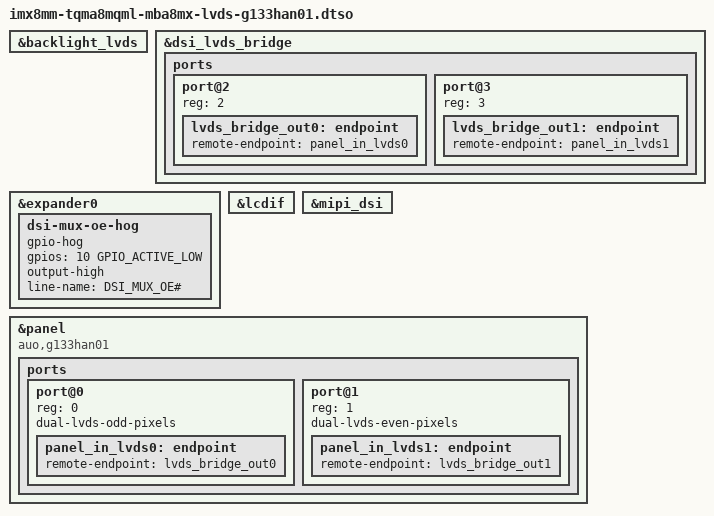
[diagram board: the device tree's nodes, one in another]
// SPDX-License-Identifier: (GPL-2.0-or-later OR MIT)
/*
 * Copyright (c) 2019-2026 TQ-Systems GmbH <linux@ew.tq-group.com>,
 * D-82229 Seefeld, Germany.
 * Author: Alexander Stein
 */

/dts-v1/;
/plugin/;

#include <dt-bindings/clock/imx8mq-clock.h>
#include <dt-bindings/gpio/gpio.h>

&backlight_lvds {
	status = "okay";
};

&dsi_lvds_bridge {
	status = "okay";

	ports {
		#address-cells = <1>;
		#size-cells = <0>;

		port@2 {
			reg = <2>;

			lvds_bridge_out0: endpoint {
				remote-endpoint = <&panel_in_lvds0>;
			};
		};

		port@3 {
			reg = <3>;

			lvds_bridge_out1: endpoint {
				remote-endpoint = <&panel_in_lvds1>;
			};
		};
	};
};

&expander0 {
	dsi-mux-oe-hog {
		gpio-hog;
		gpios = <10 GPIO_ACTIVE_LOW>;
		output-high;
		line-name = "DSI_MUX_OE#";
	};
};

&lcdif {
	status = "okay";
};

&mipi_dsi {
	status = "okay";
};

&panel {
	compatible = "auo,g133han01";
	status = "okay";

	ports {
		#address-cells = <1>;
		#size-cells = <0>;

		port@0 {
			reg = <0>;
			dual-lvds-odd-pixels;

			panel_in_lvds0: endpoint {
				remote-endpoint = <&lvds_bridge_out0>;
			};
		};

		port@1 {
			reg = <1>;
			dual-lvds-even-pixels;

			panel_in_lvds1: endpoint {
				remote-endpoint = <&lvds_bridge_out1>;
			};
		};
	};
};
